# a31g31x register map
Vendor: ABOV Semiconductor Co., Ltd.; Series: a31g31x; File version: 1.0
CPU: CM0PLUS r0p1, little endian, no MPU, no FPU, VTOR, 2 interrupt priority bits
Registers are 32-bit, read-write, reset 0x0 unless marked. A register's access mark holds for its fields unless they carry their own. Offsets are from the block's base; [hi:lo] are bit positions; {n}, {i} and the like mark numbered series.

## LCD — LCD DRIVER/CONTROLLER
Base 0x40005000
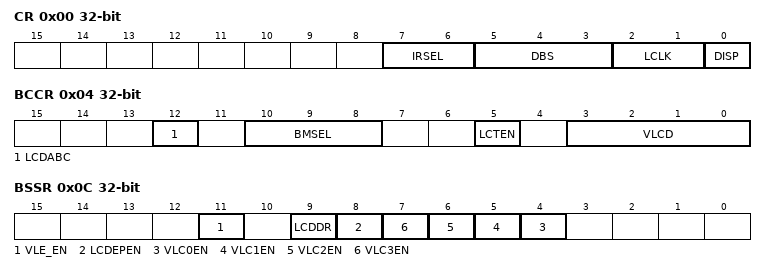
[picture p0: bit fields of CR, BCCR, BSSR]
0x00 CR — LCD Driver Control Register
  [7:6] IRSEL — Internal LCD Bias Dividing Resistor Selection bits
    0=RLCD3 (RLCD3: 105/105/80[kohm] @(1/2)/(1/3)/(1/4) bias); 1=RLCD1 (RLCD1: 10/10/10[kohm] @(1/2)/(1/3)/(1/4) bias); 2=RLCD2 (RLCD2: 66/66/50[kohm] @(1/2)/(1/3)/(1/4) bias); 3=RLCD4 (RLCD4: 320/320/240[kohm] @(1/2)/(1/3)/(1/4) bias)
  [5:3] DBS — LCD Duty and Bias Selection bits
    0=DUTY8_BIAS4 (1/8 duty, 1/4 bias); 1=DUTY6_BIAS4 (1/6 duty, 1/4 bias); 2=DUTY5_BIAS3 (1/5 duty, 1/3 bias); 3=DUTY4_BIAS3 (1/4 duty, 1/3 bias); 4=DUTY3_BIAS3 (1/3 duty, 1/3 bias); 5=DUTY3_BIAS2 (1/3 duty, 1/2 bias)
  [2:1] LCLK — LCD Clock Selection bits (When fLCD = 32.768kHz)
    0=fLCD_128Hz (128Hz); 1=fLCD_256Hz (256Hz); 2=fLCD_512Hz (512Hz); 3=fLCD_1024Hz (1024Hz)
  [0] DISP — LCD Display Control bit
    0=DISPLAY_OFF; 1=DISPLAY_ON (Normal display on)
0x04 BCCR — LCD Automatic Bias and Contrast Control Register. Notes: 1. The above LCD contrast step is based on 1/3 bias with 66kohm RLCD and on 1/4 bias with 50kohm RLCD 2. The "LCD driver contrast control" is disabled during the LCDABC bit (LCD automatic bias) is set to "1b".
  [12] LCDABC — LCD Automatic Bias Control bit
    0=LCD_AUTO_BIAS_OFF (LCD automatic bias is off); 1=LCD_AUTO_BIAS_ON (LCD automatic bias is on)
  [10:8] BMSEL — "Bias Mode A" fsTime Selection bits
    {v}="Bias Mode A" for {v+1}-clock of fLCD (v=0..7)
  [5] LCTEN — LCD Driver Contrast Control bit
    0=Disable LCD driver contrast; 1=Enable LCD driver contrast
  [3:0] VLCD — VLC0 Voltage Control when the contrast is enabled
    0=VDD x 16/31 step; 1=VDD x 16/30 step; 2=VDD x 16/29 step; 3=VDD x 16/28 step; 4=VDD x 16/27 step; 5=VDD x 16/26 step; 6=VDD x 16/25 step; 7=VDD x 16/24 step; 8=VDD x 16/23 step; 9=VDD x 16/22 step; 10=VDD x 16/21 step; 11=VDD x 16/20 step; 12=VDD x 16/19 step; 13=VDD x 16/18 step; 14=VDD x 16/17 step; 15=VDD x 16/16 step
0x0C BSSR (reset mask 0x3F0) — LCD Bias Source Selection Register is 32-bit register.
  [11] VLE_EN — LCD external bias enable register
    0=EXTBIASOFF (External bias mode OFF); 1=EXTBIASON (External bias mode ON)
  [9] LCDDR — LCD Driving Resistor for Bias Select
  [8] LCDEPEN — LCD External Bias Path Enable bit
  [n+4] VLC{n}EN (n=0..3) — Extenal Bias VLC{n} Enable bit
{0x10+i} DR{i} 8-bit (i=0..27) — LCD Display Data Register {i}

## LED — LED DRIVER/CONTROLLER
Base 0x40006000
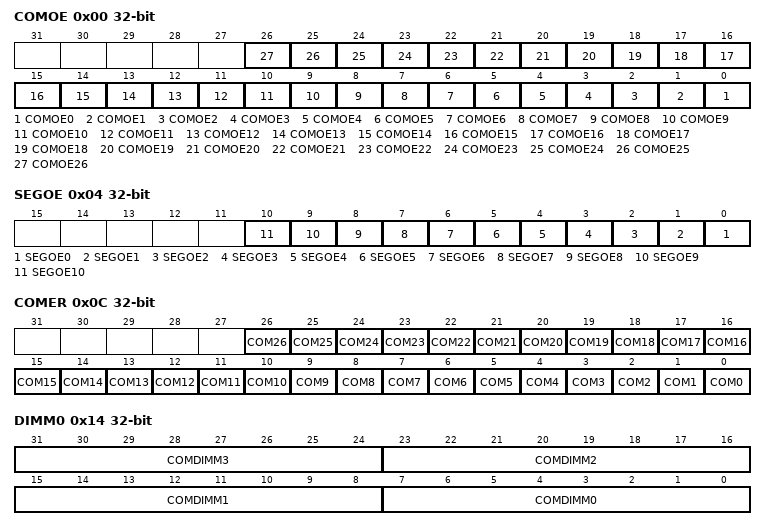
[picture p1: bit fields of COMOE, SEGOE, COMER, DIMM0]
0x00 COMOE — COM Output Enable Register
  [n] COMOE{n} (n=0..26) — COM{n} Port Mode Selection
0x04 SEGOE — SEG Output Enable Register
  [n] SEGOE{n} (n=0..10) — SEG{n} Port Mode Selection
0x08 PRESD — LED Prescaler Data Register
  [15:0] PRESD — Pre-scale value of LED clock LED Clock = fCLK/(PRESD + 1) (fCLK is a selected input clock)
0x0C COMER — COM EnableRegister
  [n] COM{n} (n=0..26) — Only Selected COM{n} is active.
0x10 COMPWID — COM Pulse Width Control Register
  [7:0] COMPWID — COM Pulse Width Control bits COM Width= LED CLK/(COMPWID + 1) (LED CLK is Prescaler output clock)
0x14 DIMM0 — COM Dimming Control Register0
  [31:24] COMDIMM3 — COM3 Dimming Control bits Dimmed COM Width = COM Width - Overlaptime - LEDCLK*COMDIMM3
  [23:16] COMDIMM2 — COM2 Dimming Control bits Dimmed COM Width = COM Width - Overlaptime- LEDCLK*COMDIMM2
  [15:8] COMDIMM1 — COM1 Dimming Control bits Dimmed COM Width = COM Width - Overlaptime - LEDCLK*COMDIMM1
  [7:0] COMDIMM0 — COM0 Dimming Control bits Dimmed COM Width = COM Width - Overlaptime - LEDCLK*COMDIMM0
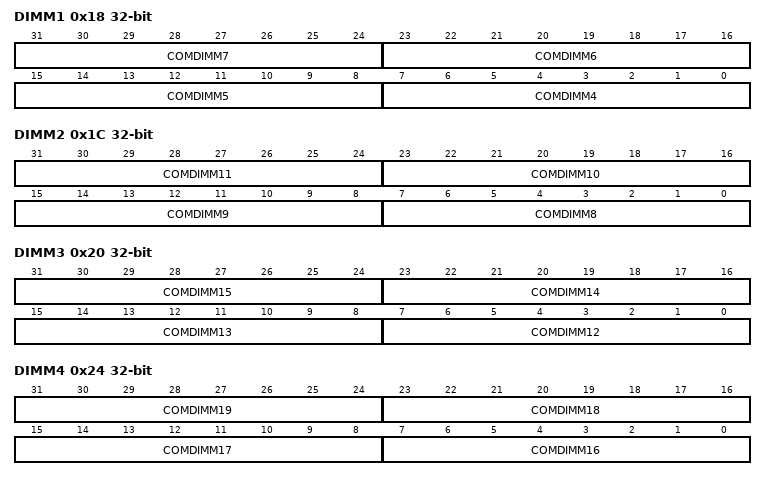
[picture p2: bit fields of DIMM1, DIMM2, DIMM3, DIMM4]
0x18 DIMM1 — COM Dimming Control Register1
  [8n-25:8n-32] COMDIMM{n} (n=4..7) — COM{n} Dimming Control bits Dimmed COM Width = COM Width - Overlaptime - LEDCLK*COMDIMM{n}
0x1C DIMM2 — COM Dimming Control Register2
  [8n-57:8n-64] COMDIMM{n} (n=8..11) — COM{n} Dimming Control bits Dimmed COM Width = COM Width - Overlaptime - LEDCLK*COMDIMM{n}
0x20 DIMM3 — COM Dimming Control Register3
  [8n-89:8n-96] COMDIMM{n} (n=12..15) — COM{n} Dimming Control bits Dimmed COM Width = COM Width - Overlaptime - LEDCLK*COMDIMM{n}
0x24 DIMM4 — COM Dimming Control Register4
  [8n-121:8n-128] COMDIMM{n} (n=16..19) — COM{n} Dimming Control bits Dimmed COM Width = COM Width - Overlaptime - LEDCLK*COMDIMM{n}
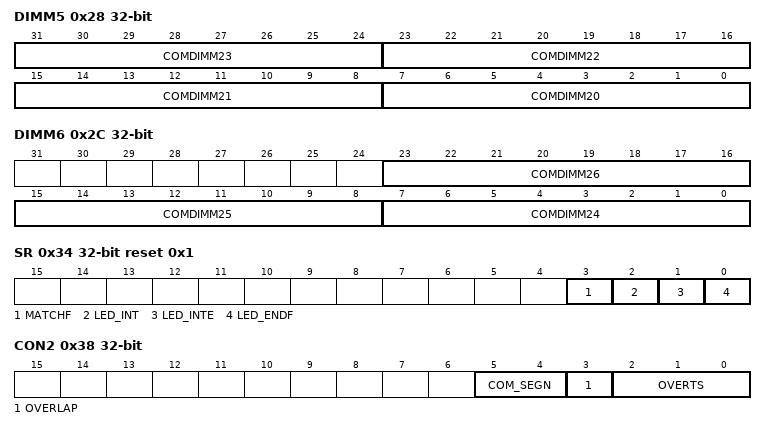
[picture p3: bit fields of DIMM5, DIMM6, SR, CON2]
0x28 DIMM5 — COM Dimming Control Register5
  [8n-153:8n-160] COMDIMM{n} (n=20..23) — COM{n} Dimming Control bits Dimmed COM Width = COM Width - Overlaptime - LEDCLK*COMDIMM{n}
0x2C DIMM6 — COM Dimming Control Register0
  [23:16] COMDIMM26 — COM26 Dimming Control bits Dimmed COM Width = COM Width - Overlaptime - LEDCLK*COMDIMM26
  [15:8] COMDIMM25 — COM25 Dimming Control bits Dimmed COM Width = COM Width - Overlaptime - LEDCLK*COMDIMM25
  [7:0] COMDIMM24 — COM24 Dimming Control bits Dimmed COM Width = COM Width - Overlaptime - LEDCLK*COMDIMM24
0x30 STPD — LED STOP Duration Register
  [19:0] LEDSTPD — LED STOP Duration Register (since LED Start)
0x34 SR reset 0x1 — LED STATUS Register
  [3] MATCHF — Flag to occur when LEDSTPD reg match with counter
  [2] LED_INT — LED Interrupt Flag(in LED_INTE=1)
  [1] LED_INTE — LED Interrupt Enable
  [0] LED_ENDF — LED Operation End Flag
0x38 CON2 — LED Control Register2
  [5:4] COM_SEGN — COM & SEG Share Pin Select
  [3] OVERLAP — OVERLAP TIME Select
  [2:0] OVERTS — OVERLAP TIME Select
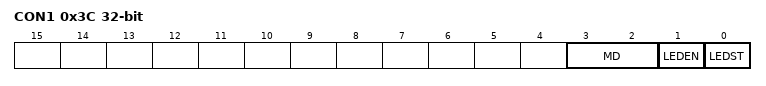
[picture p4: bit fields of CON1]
0x3C CON1 — LED Control Register1
  [3:2] MD — Mode Select
  [1] LEDEN — LED Enable
  [0] LEDST — LED START, STOP Operation
{0x44+4i} DISPRAM{i} (i=0..20) — LED Display data {i}
0x98 DISPRAM21 — LED Display data 28
{0x44+4i} DISPRAM{i} (i=22..26) — LED Display data {i}

## CRC — CYCLIC REDUNDANCY CHECK AND CHECKSUM
Base 0x40000300
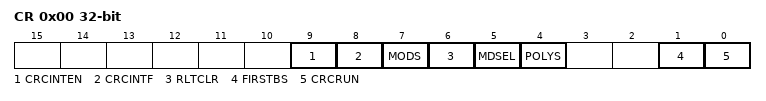
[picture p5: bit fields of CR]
0x00 CR — CRC/Checksum Control Register. Notes: 1. The CRCRLT register and the CRC/Checksum block should be initialized by writing "1b" to the RLTCLR bit before a new CRC/Checksum calculation. 2. The CRCRUN bit should be set to "1b" last time after setting appropriate values to the registers. 3. On the user mode, it will be calculated every writing data to the CRCIN register during CRCRUN==1. 4. On the user mode with SARINC==0, the block is finished by writing "0b" to the CRCRUN bit. 4. It is prohibited writing any data to the CRCIN register during CRCRUN==0. 5. The checksum is calculated by byte unit. Ex) On 0x34A7E991, CRCRLT = 0x34 + 0xA7 + 0xE9 + 0x91.
  [9] CRCINTEN — CRC interrupt enable bit
  [8] CRCINTF — CRC interrupt flag bit
  [7] MODS — User/Auto Mode Selection bit
  [6] RLTCLR — CRC/Checksum Result Data Register (CRCRLT) Initialization bit
  [5] MDSEL — CRC/Checksum Selection bit
  [4] POLYS — Polynomial Selection bit (CRC only)
  [1] FIRSTBS — First Shifted-in Selection bit (CRC only)
  [0] CRCRUN — CRC/Checksum Start Control and Busy bit
0x04 IN — CRC/Checksum Input Data Register
0x08 RLT ro reset 0xFFFF — CRC/Checksum Result Data Register
0x0C INIT — CRC/Checksum Initial Data Register

## Notices in the file
Copyright (C) 2012-2014 ARM Limited. All rights reserved.
Purpose: System Viewer Description (SVD) Example (Schema Version 1.1)
This is a description of a none-existent and incomplete device
for demonstration purposes only.
Redistribution and use in source and binary forms, with or without
modification, are permitted provided that the following conditions are met:
- Redistributions of source code must retain the above copyright
notice, this list of conditions and the following disclaimer.
- Redistributions in binary form must reproduce the above copyright
notice, this list of conditions and the following disclaimer in the
documentation and/or other materials provided with the distribution.
- Neither the name of ARM nor the names of its contributors may be used
to endorse or promote products derived from this software without
specific prior written permission.
THIS SOFTWARE IS PROVIDED BY THE COPYRIGHT HOLDERS AND CONTRIBUTORS "AS IS"
AND ANY EXPRESS OR IMPLIED WARRANTIES, INCLUDING, BUT NOT LIMITED TO, THE
IMPLIED WARRANTIES OF MERCHANTABILITY AND FITNESS FOR A PARTICULAR PURPOSE
ARE DISCLAIMED. IN NO EVENT SHALL COPYRIGHT HOLDERS AND CONTRIBUTORS BE
LIABLE FOR ANY DIRECT, INDIRECT, INCIDENTAL, SPECIAL, EXEMPLARY, OR
CONSEQUENTIAL DAMAGES (INCLUDING, BUT NOT LIMITED TO, PROCUREMENT OF
SUBSTITUTE GOODS OR SERVICES; LOSS OF USE, DATA, OR PROFITS; OR BUSINESS
INTERRUPTION) HOWEVER CAUSED AND ON ANY THEORY OF LIABILITY, WHETHER IN
CONTRACT, STRICT LIABILITY, OR TORT (INCLUDING NEGLIGENCE OR OTHERWISE)
ARISING IN ANY WAY OUT OF THE USE OF THIS SOFTWARE, EVEN IF ADVISED OF THE
POSSIBILITY OF SUCH DAMAGE.
